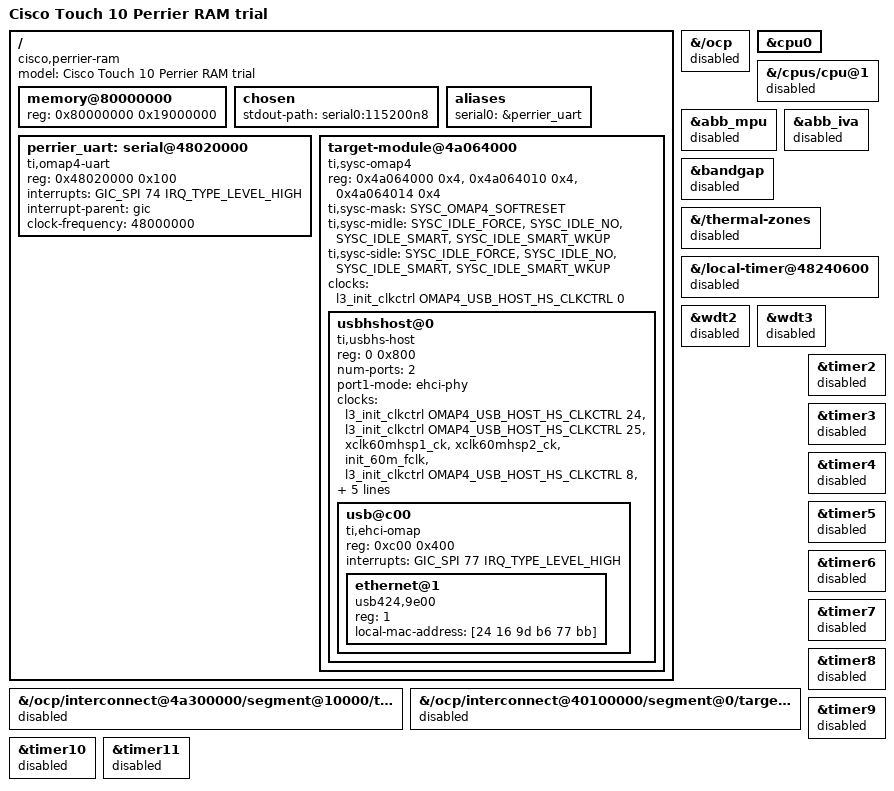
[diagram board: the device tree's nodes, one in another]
// SPDX-License-Identifier: GPL-2.0-only
// Second RAM trial: known UART and the stock USB-attached LAN controller.
/dts-v1/;
#include "omap4460.dtsi"

/ {
    model = "Cisco Touch 10 Perrier RAM trial";
    compatible = "cisco,perrier-ram", "ti,omap4460", "ti,omap4";
    memory@80000000 {
        device_type = "memory";
        reg = <0x80000000 0x19000000>; // observed low 400 MiB only
    };
    chosen {
        stdout-path = "serial0:115200n8";
    };
    aliases {
        serial0 = &perrier_uart;
        /delete-property/ serial1;
        /delete-property/ serial2;
        /delete-property/ serial3;
    };
    // Stock UART3 is already muxed and clocked at 48 MHz. No pad/GPIO writes.
    perrier_uart: serial@48020000 {
        compatible = "ti,omap4-uart";
        reg = <0x48020000 0x100>;
        interrupts = <GIC_SPI 74 IRQ_TYPE_LEVEL_HIGH>;
        interrupt-parent = <&gic>;
        clock-frequency = <48000000>;
    };

    // Only the OMAP USB host target is populated. Its port 1 connects to the
    // board's already powered external PHY and SMSC95xx LAN chip. The stock
    // GPIO/pad state is inherited across kexec; this DT makes no GPIO writes.
    target-module@4a064000 {
        compatible = "ti,sysc-omap4", "ti,sysc";
        reg = <0x4a064000 0x4>, <0x4a064010 0x4>, <0x4a064014 0x4>;
        reg-names = "rev", "sysc", "syss";
        ti,sysc-mask = <SYSC_OMAP4_SOFTRESET>;
        ti,sysc-midle = <SYSC_IDLE_FORCE>, <SYSC_IDLE_NO>,
                         <SYSC_IDLE_SMART>, <SYSC_IDLE_SMART_WKUP>;
        ti,sysc-sidle = <SYSC_IDLE_FORCE>, <SYSC_IDLE_NO>,
                         <SYSC_IDLE_SMART>, <SYSC_IDLE_SMART_WKUP>;
        clocks = <&l3_init_clkctrl OMAP4_USB_HOST_HS_CLKCTRL 0>;
        clock-names = "fck";
        #address-cells = <1>;
        #size-cells = <1>;
        ranges = <0 0x4a064000 0x1000>;

        usbhshost@0 {
            compatible = "ti,usbhs-host";
            reg = <0 0x800>;
            num-ports = <2>;
            port1-mode = "ehci-phy";
            #address-cells = <1>;
            #size-cells = <1>;
            ranges = <0 0 0x1000>;
            clocks = <&l3_init_clkctrl OMAP4_USB_HOST_HS_CLKCTRL 24>,
                     <&l3_init_clkctrl OMAP4_USB_HOST_HS_CLKCTRL 25>,
                     <&xclk60mhsp1_ck>, <&xclk60mhsp2_ck>,
                     <&init_60m_fclk>,
                     <&l3_init_clkctrl OMAP4_USB_HOST_HS_CLKCTRL 8>,
                     <&l3_init_clkctrl OMAP4_USB_HOST_HS_CLKCTRL 9>,
                     <&l3_init_clkctrl OMAP4_USB_HOST_HS_CLKCTRL 13>,
                     <&l3_init_clkctrl OMAP4_USB_HOST_HS_CLKCTRL 14>,
                     <&l3_init_clkctrl OMAP4_USB_HOST_HS_CLKCTRL 11>,
                     <&l3_init_clkctrl OMAP4_USB_HOST_HS_CLKCTRL 12>;
            clock-names = "utmi_p1_gfclk", "utmi_p2_gfclk",
                          "refclk_60m_ext_p1", "refclk_60m_ext_p2",
                          "refclk_60m_int",
                          "usb_host_hs_utmi_p1_clk", "usb_host_hs_utmi_p2_clk",
                          "usb_host_hs_hsic480m_p1_clk", "usb_host_hs_hsic480m_p2_clk",
                          "usb_host_hs_hsic60m_p1_clk", "usb_host_hs_hsic60m_p2_clk";

            usb@c00 {
                compatible = "ti,ehci-omap";
                reg = <0xc00 0x400>;
                interrupts = <GIC_SPI 77 IRQ_TYPE_LEVEL_HIGH>;
                #address-cells = <1>;
                #size-cells = <0>;

                ethernet@1 {
                    compatible = "usb424,9e00";
                    reg = <1>;
                    local-mac-address = [24 16 9d b6 77 bb];
                };
            };
        };
    };
};

// Do not populate generic peripheral targets. Early OF clock and timer
// initialization uses the retained SoC descriptions independently of this bus.
&{/ocp} { status = "disabled"; };
&cpu0 { /delete-property/ operating-points; };
&{/cpus/cpu@1} { status = "disabled"; };
&abb_mpu { status = "disabled"; };
&abb_iva { status = "disabled"; };
&bandgap { status = "disabled"; };
&{/thermal-zones} { status = "disabled"; };
&{/local-timer@48240600} { status = "disabled"; };

// Both watchdog targets must be invisible to ti-sysc and watchdog drivers.
&wdt2 { status = "disabled"; };
&wdt3 { status = "disabled"; };
&{/ocp/interconnect@4a300000/segment@10000/target-module@4000} {
    status = "disabled";
};
&{/ocp/interconnect@40100000/segment@0/target-module@30000} {
    status = "disabled";
};
// Prevent early timer discovery from choosing another board's peripheral.
&timer2 { status = "disabled"; };
&timer3 { status = "disabled"; };
&timer4 { status = "disabled"; };
&timer5 { status = "disabled"; };
&timer6 { status = "disabled"; };
&timer7 { status = "disabled"; };
&timer8 { status = "disabled"; };
&timer9 { status = "disabled"; };
&timer10 { status = "disabled"; };
&timer11 { status = "disabled"; };
